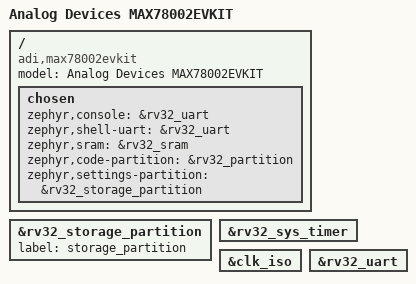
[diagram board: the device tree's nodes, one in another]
/*
 * Copyright (c) 2026 Analog Devices, Inc.
 *
 * SPDX-License-Identifier: Apache-2.0
 */

/dts-v1/;

#include <adi/max32/max78002-rv32.dtsi>
#include "max78002evkit.dtsi"

#include <adi/max32/max78002-pinctrl.dtsi>

&rv32_storage_partition {
	label = "storage_partition";
};

/ {
	model = "Analog Devices MAX78002EVKIT";
	compatible = "adi,max78002evkit";

	chosen {
		zephyr,console = &rv32_uart;
		zephyr,shell-uart = &rv32_uart;
		zephyr,sram = &rv32_sram;
		zephyr,code-partition = &rv32_partition;
		zephyr,settings-partition = &rv32_storage_partition;
	};
};

&rv32_sys_timer {
	status = "okay";
};

&clk_iso {
	status = "okay";
};

&rv32_uart {
	status = "okay";
};
